# System_Clock_2 register map
Vendor: Texas Instruments
Peripheral module from a debugger description file (folder msp430).
Registers are 8-bit, read-write, reset 0x0 unless marked. A register's access mark holds for its fields unless they carry their own. Offsets are as the file gives them; lines under a group give offsets from that group; [hi:lo] are bit positions; {n}, {i} and the like mark numbered series; 'fields as' and 'values as' point back to an identical list; <NAME> marks a mode.

## System_Clock
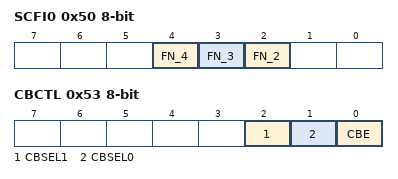
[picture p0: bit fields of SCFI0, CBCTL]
0x50 SCFI0 — System Clock Frequency Integrator 0
  [4] FN_4, [3] FN_3, [2] FN_2
0x51 SCFI1 access not given reset not defined — System Clock Frequency Integrator 1
0x52 SCFQCTL access not given reset not defined — System Clock Frequency Control
0x53 CBCTL — Crystal Buffer Control *** WRITE-ONLY ***
  [2] CBSEL1, [1] CBSEL0, [0] CBE
